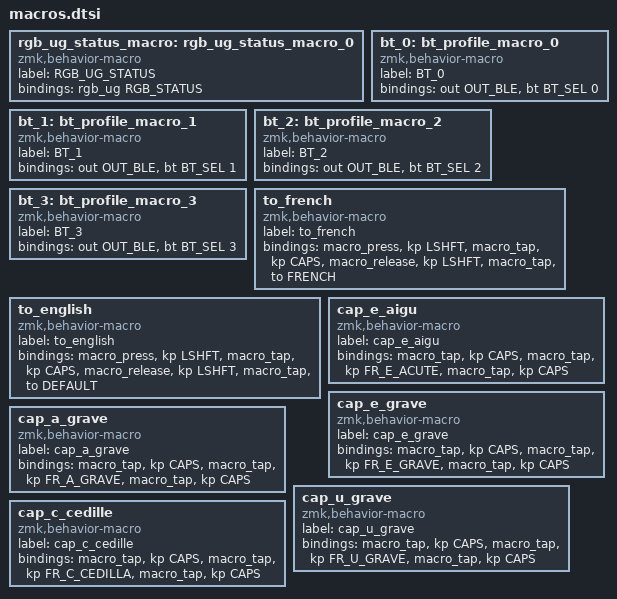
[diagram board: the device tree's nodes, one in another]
// bluetooth macros
rgb_ug_status_macro: rgb_ug_status_macro_0 {
    label = "RGB_UG_STATUS";
    compatible = "zmk,behavior-macro";
    #binding-cells = <0>;
    bindings
        = <&rgb_ug RGB_STATUS>;
};

bt_0: bt_profile_macro_0 {
    label = "BT_0";
    compatible = "zmk,behavior-macro";
    #binding-cells = <0>;
    bindings
        = <&out OUT_BLE>,
          <&bt BT_SEL 0>;
};

bt_1: bt_profile_macro_1 {
    label = "BT_1";
    compatible = "zmk,behavior-macro";
    #binding-cells = <0>;
    bindings
        = <&out OUT_BLE>,
          <&bt BT_SEL 1>;
};

bt_2: bt_profile_macro_2 {
    label = "BT_2";
    compatible = "zmk,behavior-macro";
    #binding-cells = <0>;
    bindings
        = <&out OUT_BLE>,
          <&bt BT_SEL 2>;
};

bt_3: bt_profile_macro_3 {
    label = "BT_3";
    compatible = "zmk,behavior-macro";
    #binding-cells = <0>;
    bindings
        = <&out OUT_BLE>,
          <&bt BT_SEL 3>;
};

// french macros
to_french: to_french {
	label = "to_french";
            compatible = "zmk,behavior-macro";
            #binding-cells = <0>;
            bindings
                = <&macro_press &kp LSHFT>
                , <&macro_tap &kp CAPS>
                , <&macro_release &kp LSHFT>
                , <&macro_tap &to FRENCH>
                ;
};

to_english: to_english {
	label = "to_english";
            compatible = "zmk,behavior-macro";
            #binding-cells = <0>;
            bindings
                = <&macro_press &kp LSHFT>
                , <&macro_tap &kp CAPS>
                , <&macro_release &kp LSHFT>
                , <&macro_tap &to DEFAULT>
                ;
};

cap_e_aigu: cap_e_aigu {
	label = "cap_e_aigu";
            compatible = "zmk,behavior-macro";
            #binding-cells = <0>;
            bindings
                = <&macro_tap &kp CAPS>
                , <&macro_tap &kp FR_E_ACUTE>
                , <&macro_tap &kp CAPS>
                ;
};

cap_e_grave: cap_e_grave {
	label = "cap_e_grave";
            compatible = "zmk,behavior-macro";
            #binding-cells = <0>;
            bindings
                = <&macro_tap &kp CAPS>
                , <&macro_tap &kp FR_E_GRAVE>
                , <&macro_tap &kp CAPS>
                ;
};

cap_a_grave: cap_a_grave {
	label = "cap_a_grave";
            compatible = "zmk,behavior-macro";
            #binding-cells = <0>;
            bindings
                = <&macro_tap &kp CAPS>
                , <&macro_tap &kp FR_A_GRAVE>
                , <&macro_tap &kp CAPS>
                ;
};

cap_u_grave: cap_u_grave {
	label = "cap_u_grave";
            compatible = "zmk,behavior-macro";
            #binding-cells = <0>;
            bindings
                = <&macro_tap &kp CAPS>
                , <&macro_tap &kp FR_U_GRAVE>
                , <&macro_tap &kp CAPS>
                ;
};

cap_c_cedille: cap_c_cedille {
	label = "cap_c_cedille";
            compatible = "zmk,behavior-macro";
            #binding-cells = <0>;
            bindings
                = <&macro_tap &kp CAPS>
                , <&macro_tap &kp FR_C_CEDILLA>
                , <&macro_tap &kp CAPS>
                ;
};
